# RP2350 register map
Vendor: Raspberry Pi; File version: 0.1
CPU: CM33 r1p0, little endian, MPU, FPU, VTOR, 4 interrupt priority bits, 54 interrupts, 8 SAU regions
Registers are 32-bit, read-write, reset 0x0 unless marked. A register's access mark holds for its fields unless they carry their own. Offsets are from the block's base; [hi:lo] are bit positions; {n}, {i} and the like mark numbered series.

## TRNG — ARM TrustZone RNG register block
Base 0x400F0000
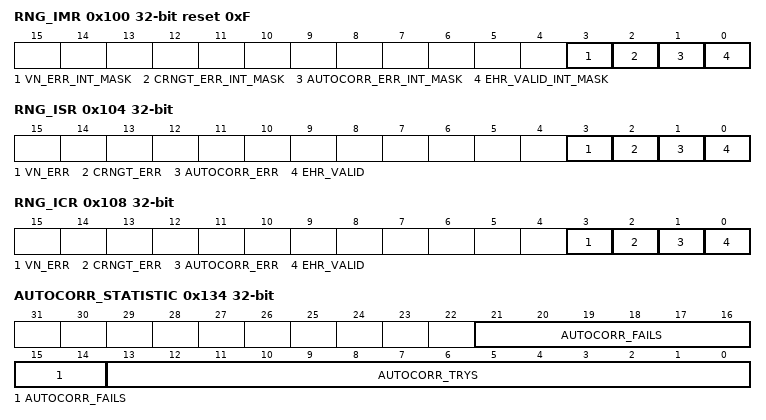
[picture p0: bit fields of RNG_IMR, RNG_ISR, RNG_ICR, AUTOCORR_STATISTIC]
0x100 RNG_IMR access per field reset 0xF — Interrupt masking.
  [3] VN_ERR_INT_MASK rw — 1'b1-mask interrupt, no interrupt will be generated. See RNG_ISR for an explanation on this interrupt.
  [2] CRNGT_ERR_INT_MASK rw — 1'b1-mask interrupt, no interrupt will be generated. See RNG_ISR for an explanation on this interrupt.
  [1] AUTOCORR_ERR_INT_MASK rw — 1'b1-mask interrupt, no interrupt will be generated. See RNG_ISR for an explanation on this interrupt.
  [0] EHR_VALID_INT_MASK rw — 1'b1-mask interrupt, no interrupt will be generated. See RNG_ISR for an explanation on this interrupt.
0x104 RNG_ISR ro — RNG status register. If corresponding RNG_IMR bit is unmasked, an interrupt will be generated.
  [3] VN_ERR — 1'b1 indicates Von Neuman error. Error in von Neuman occurs if 32 consecutive collected bits are identical, ZERO or ONE.
  [2] CRNGT_ERR — 1'b1 indicates CRNGT in the RNG test failed. Failure occurs when two consecutive blocks of 16 collected bits are equal.
  [1] AUTOCORR_ERR — 1'b1 indicates Autocorrelation test failed four times in a row. When set, RNG cease from functioning until next reset.
  [0] EHR_VALID — 1'b1 indicates that 192 bits have been collected in the RNG, and are ready to be read.
0x108 RNG_ICR access per field — Interrupt/status bit clear Register.
  [3] VN_ERR rw — Write 1'b1 - clear corresponding bit in RNG_ISR.
  [2] CRNGT_ERR rw — Write 1'b1 - clear corresponding bit in RNG_ISR.
  [1] AUTOCORR_ERR rw — Cannot be cleared by SW! Only RNG reset clears this bit.
  [0] EHR_VALID rw — Write 1'b1 - clear corresponding bit in RNG_ISR.
0x10C TRNG_CONFIG access per field — Selecting the inverter-chain length.
  [1:0] RND_SRC_SEL rw — Selects the number of inverters (out of four possible selections) in the ring oscillator (the entropy source).
0x110 TRNG_VALID ro — 192 bit collection indication.
  [0] EHR_VALID — 1'b1 indicates that collection of bits in the RNG is completed, and data can be read from EHR_DATA register.
{0x114+4i} EHR_DATA{i} ro (i=0..5) — RNG collected bits. Bits [{32i+31}:{32i}] of Entropy Holding Register (EHR) - RNG output register
0x12C RND_SOURCE_ENABLE access per field — Enable signal for the random source.
  [0] RND_SRC_EN rw — * 1'b1 - entropy source is enabled. *1'b0 - entropy source is disabled
0x130 SAMPLE_CNT1 reset 0xFFFF — Counts clocks between sampling of random bit.
  [31:0] SAMPLE_CNTR1 — Sets the number of rng_clk cycles between two consecutive ring oscillator samples. Note! If the Von-Neuman is bypassed, the minimum value for sample counter must not be less then decimal seventeen
0x134 AUTOCORR_STATISTIC access per field — Statistic about Autocorrelation test activations.
  [21:14] AUTOCORR_FAILS rw — Count each time an autocorrelation test fails. Any write to the register reset the counter. Stop collecting statistic if one of the counters reached the limit.
  [13:0] AUTOCORR_TRYS rw — Count each time an autocorrelation test starts. Any write to the register reset the counter. Stop collecting statistic if one of the counters reached the limit.
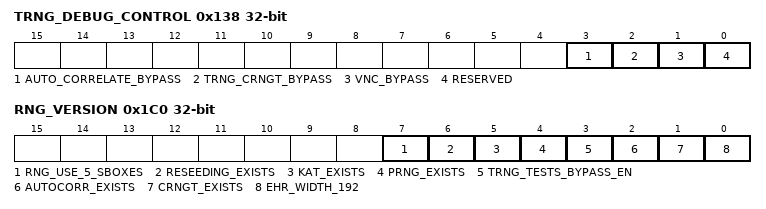
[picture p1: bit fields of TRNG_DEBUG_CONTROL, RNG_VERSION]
0x138 TRNG_DEBUG_CONTROL access per field — Debug register.
  [3] AUTO_CORRELATE_BYPASS rw — When set, the autocorrelation test in the TRNG module is bypassed.
  [2] TRNG_CRNGT_BYPASS rw — When set, the CRNGT test in the RNG is bypassed.
  [1] VNC_BYPASS rw — When set, the Von-Neuman balancer is bypassed (including the 32 consecutive bits test).
  [0] RESERVED ro
0x140 TRNG_SW_RESET access per field — Generate internal SW reset within the RNG block.
  [0] TRNG_SW_RESET rw — Writing 1'b1 to this register causes an internal RNG reset.
0x1B4 RNG_DEBUG_EN_INPUT access per field — Enable the RNG debug mode
  [0] RNG_DEBUG_EN rw — * 1'b1 - debug mode is enabled. *1'b0 - debug mode is disabled
0x1B8 TRNG_BUSY ro — RNG Busy indication.
  [0] TRNG_BUSY — Reflects rng_busy status.
0x1BC RST_BITS_COUNTER access per field — Reset the counter of collected bits in the RNG.
  [0] RST_BITS_COUNTER rw — Writing any value to this address will reset the bits counter and RNG valid registers. RND_SORCE_ENABLE register must be unset in order for the reset to take place.
0x1C0 RNG_VERSION ro — Displays the version settings of the TRNG.
  [7] RNG_USE_5_SBOXES — * 1'b1 - 5 SBOX AES. *1'b0 - 20 SBOX AES
  [6] RESEEDING_EXISTS — * 1'b1 - Exists. *1'b0 - Does not exist
  [5] KAT_EXISTS — * 1'b1 - Exists. *1'b0 - Does not exist
  [4] PRNG_EXISTS — * 1'b1 - Exists. *1'b0 - Does not exist
  [3] TRNG_TESTS_BYPASS_EN — * 1'b1 - Exists. *1'b0 - Does not exist
  [2] AUTOCORR_EXISTS — * 1'b1 - Exists. *1'b0 - Does not exist
  [1] CRNGT_EXISTS — * 1'b1 - Exists. *1'b0 - Does not exist
  [0] EHR_WIDTH_192 — * 1'b1 - 192-bit EHR. *1'b0 - 128-bit EHR
{0x1E0+4i} RNG_BIST_CNTR_{i} ro (i=0..2) — Collected BIST results.
  [21:0] ROSC_CNTR_VAL — Reflects the results of RNG BIST counter.
